# Qorvo_SVD register map
Vendor: Qorvo Inc; Series: ARMCM4; File version: 1.0
ARM CM4 device.
Registers are 8-bit, read-write, reset 0x0 unless marked. A register's access mark holds for its fields unless they carry their own. Offsets are from the block's base; lines under a group give offsets from that group; [hi:lo] are bit positions; {n}, {i} and the like mark numbered series; 'fields as' and 'values as' point back to an identical list; <NAME> marks a mode.

## Memory map
0x40000700 IOB
0x40000900 ES
0x40000B00 INT_CTRL
0x40000C40 CORTEXM4
0x40001000 GPIO
0x40001020 I2C_M
0x40001040 ADCIF
0x40001080 SSP
0x400010A0 UART_0
0x400010B0 UART_1
0x400010D0 SPI_M
0x400010E0 KEYPAD
0x40001100 IR
0x40001120 WATCHDOG
0x40001140 LEDS
0x400011C0 SPI_SL
0x400011E0 I2C_SL
0x40001200 DMAS
0x40001300 I2S_M
0x40001320 ASP
0x40001400 PWMS

## CORTEXM4
Base 0x40000C40
0x00 CORTEXM4_0X00000000[0]
  [7:0] VECTOR_TABLE_OFFSET[0] — Offset in 256 byte multiples for the vector table
0x01 CORTEXM4_0X00000000[1] reset 0x80
  [7:0] VECTOR_TABLE_OFFSET[1] — Offset in 256 byte multiples for the vector table
0x02 CORTEXM4_0X00000000[2] reset 0x4
  [6:0] VECTOR_TABLE_OFFSET[2] — Offset in 256 byte multiples for the vector table
0x04 CORTEXM4_0X00000004[0]
  [7:0] SYSTICK_CALIB[0] — Should be set to the value in order to a 10 ms delay from the FCLK. So needs to change when FCLK changes frequency
0x05 CORTEXM4_0X00000004[1] reset 0x71
  [7:0] SYSTICK_CALIB[1] — Should be set to the value in order to a 10 ms delay from the FCLK. So needs to change when FCLK changes frequency
0x06 CORTEXM4_0X00000004[2] reset 0x2
  [7:0] SYSTICK_CALIB[2] — Should be set to the value in order to a 10 ms delay from the FCLK. So needs to change when FCLK changes frequency
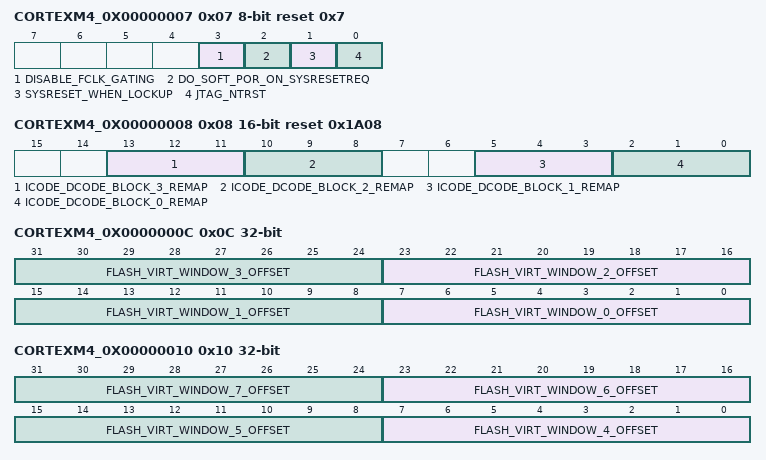
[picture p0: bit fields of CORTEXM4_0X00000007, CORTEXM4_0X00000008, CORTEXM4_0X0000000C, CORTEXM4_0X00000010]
0x07 CORTEXM4_0X00000007 reset 0x7
  [3] DISABLE_FCLK_GATING — by default fclk is also gated - this bit allows fdor disabling this clk gating feature - REQUIRED when ENABLING DEBUG INTERFACE !
  [2] DO_SOFT_POR_ON_SYSRESETREQ — When set, a sysreset req (triggered from debug interface, will trigger a soft por (POR_REASON_SOFT_POR_PRESERVE_DBG_ITF)
  [1] SYSRESET_WHEN_LOCKUP — This enables the sysreset on lockup feature. So when a lockup happens, this will trigger a system reset
  [0] JTAG_NTRST — TRSTn pin for the JTAG interface
0x08 CORTEXM4_0X00000008 16-bit reset 0x1A08
  [13:11] ICODE_DCODE_BLOCK_3_REMAP — logical to physical block remapping on dcode and icode mem interface for block 3 (allowed values 0 to 3, bit 2 is reserved)
  [10:8] ICODE_DCODE_BLOCK_2_REMAP — logical to physical block remapping on dcode and icode mem interface for block 2 (allowed values 0 to 3, bit 2 is reserved)
  [5:3] ICODE_DCODE_BLOCK_1_REMAP — logical to physical block remapping on dcode and icode mem interface for block 1 (allowed values 0 to 3, bit 2 is reserved)
  [2:0] ICODE_DCODE_BLOCK_0_REMAP — logical to physical block remapping on dcode and icode mem interface for block 0 (allowed values 0 to 3, bit 2 is reserved)
0x0C CORTEXM4_0X0000000C 32-bit
  [8n+7:8n] FLASH_VIRT_WINDOW_{n}_OFFSET (n=0..3) — offset redirecting the 4kB virtual icode/dcode flash window {n} into the main flash array
0x10 CORTEXM4_0X00000010 32-bit
  [8n-25:8n-32] FLASH_VIRT_WINDOW_{n}_OFFSET (n=4..7) — offset redirecting the 4kB virtual icode/dcode flash window {n} into the main flash array
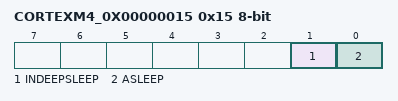
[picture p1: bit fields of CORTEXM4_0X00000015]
0x15 CORTEXM4_0X00000015 ro
  [1] INDEEPSLEEP — Indicates that the processor is in deep sleep mode
  [0] ASLEEP — Indicates that the processor is in sleep mode

## GPIO
Base 0x40001000
0x00 GPIO_GPIO_CLOCK_ENABLE reset 0x1
  [0] GPIO_CLOCK_ENABLE — Gpio clock enabled when 0x1
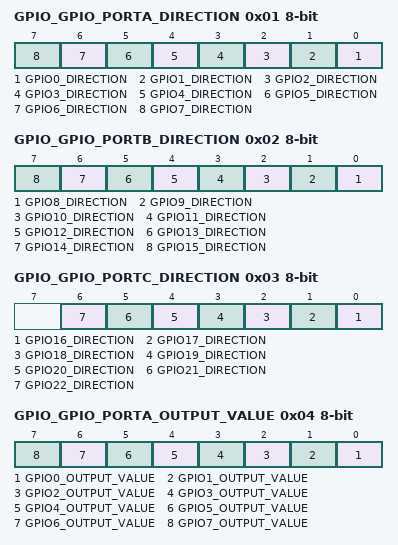
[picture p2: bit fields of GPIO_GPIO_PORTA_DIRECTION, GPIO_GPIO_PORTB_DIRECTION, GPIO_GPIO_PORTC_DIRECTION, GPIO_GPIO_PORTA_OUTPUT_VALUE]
0x01 GPIO_GPIO_PORTA_DIRECTION
  [n] GPIO{n}_DIRECTION (n=0..7) — 0 = input, 1 = output
0x02 GPIO_GPIO_PORTB_DIRECTION
  [n-8] GPIO{n}_DIRECTION (n=8..15) — 0 = input, 1 = output
0x03 GPIO_GPIO_PORTC_DIRECTION
  [n-16] GPIO{n}_DIRECTION (n=16..22) — 0 = input, 1 = output
0x04 GPIO_GPIO_PORTA_OUTPUT_VALUE
  [n] GPIO{n}_OUTPUT_VALUE (n=0..7)
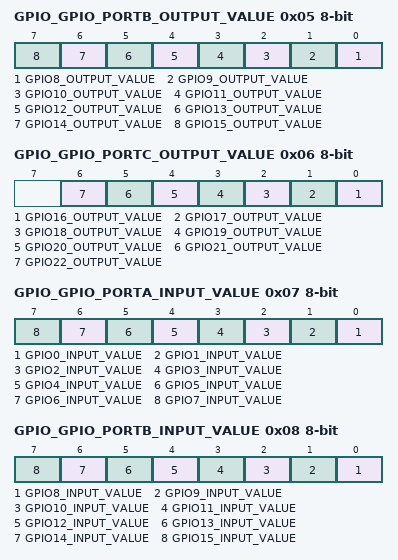
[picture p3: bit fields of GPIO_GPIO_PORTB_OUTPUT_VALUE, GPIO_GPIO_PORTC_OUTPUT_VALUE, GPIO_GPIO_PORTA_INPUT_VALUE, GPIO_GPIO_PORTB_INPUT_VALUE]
0x05 GPIO_GPIO_PORTB_OUTPUT_VALUE
  [n-8] GPIO{n}_OUTPUT_VALUE (n=8..15)
0x06 GPIO_GPIO_PORTC_OUTPUT_VALUE
  [n-16] GPIO{n}_OUTPUT_VALUE (n=16..22)
0x07 GPIO_GPIO_PORTA_INPUT_VALUE ro
  [n] GPIO{n}_INPUT_VALUE (n=0..7)
0x08 GPIO_GPIO_PORTB_INPUT_VALUE ro
  [n-8] GPIO{n}_INPUT_VALUE (n=8..15)
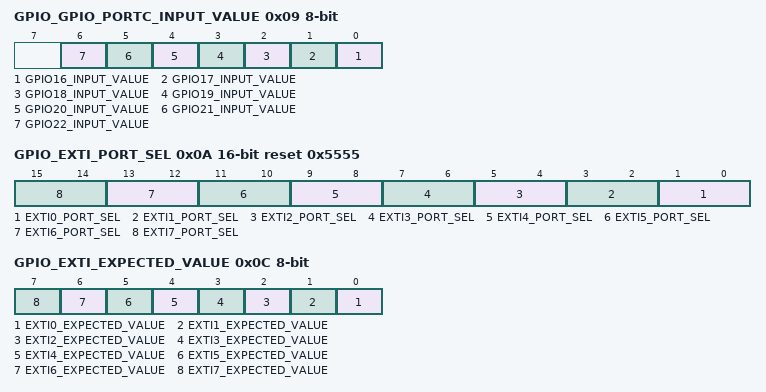
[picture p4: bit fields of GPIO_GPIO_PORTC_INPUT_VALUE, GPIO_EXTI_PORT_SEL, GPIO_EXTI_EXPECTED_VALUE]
0x09 GPIO_GPIO_PORTC_INPUT_VALUE ro
  [n-16] GPIO{n}_INPUT_VALUE (n=16..22)
0x0A GPIO_EXTI_PORT_SEL 16-bit reset 0x5555
  [2n+1:2n] EXTI{n}_PORT_SEL (n=0..7) — Select the correct port for the exti{n} interrupt
0x0C GPIO_EXTI_EXPECTED_VALUE
  [n] EXTI{n}_EXPECTED_VALUE (n=0..7) — Expected value for the pin associated with exti{n} interrupt
0x0D GPIO_UNMASKED_INTERRUPTS ro
  [n] UNMASKED_EXTI{n}_INTERRUPT (n=0..7) — Unmasked Interrupt event, set to 0x1 when detected
  [7:0] UNMASKED_EXTI_INTERRUPTS — Unmasked Interrupt event, set to 0x1 when detected
